AUTOSAR XML (schema 4-2-2)
package /ServiceApplTemplate/SwComponentTypes
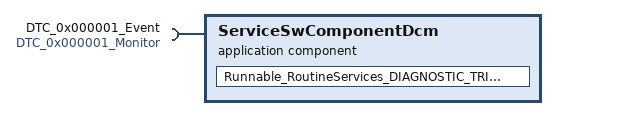
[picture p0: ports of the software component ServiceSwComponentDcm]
  application sw component type ServiceSwComponentDcm
    require port DTC_0x000001_Event: required-interface=DTC_0x000001_Monitor
    behavior ServiceSwComponentDcm_IB: handle-termination-and-restart=NO-SUPPORT
      runnable Runnable_RoutineServices_DIAGNOSTIC_TRIGGER_DTC_A5663192471BAAA2C67D187118DC8330: symbol=ServiceSwComponentDcm_RoutineServices_DIAGNOSTIC_TRIGGER_DTC_Start
        sync call SetEventStatus: operation=DTC_0x000001_Event.SetEventStatus, timeout=0.0
package /DemoApplication/SwComponentTypes
  composition sw component type TopLevelComposition
    component ServiceSwComponentDcm: type=ServiceSwComponentDcm
    connect Dem_Prototype.Event_DTC_0x000001_Event -> ServiceSwComponentDcm.DTC_0x000001_Event
package /PortInterfaces
  client server interface DTC_0x000001_Monitor: is-service=true
    operation SetEventStatus: possible-error=[E_NOT_OK, E_OK]
      arg EventStatus: type=Dem_EventStatusType, direction=IN
    error E_NOT_OK: error-code=1
    error E_OK: error-code=0
package /CompuMethods
  compu method CM_EventStatusType: 0=DEM_EVENT_STATUS_PASSED, 1=DEM_EVENT_STATUS_FAILED, 2=DEM_EVENT_STATUS_PREPASSED, 3=DEM_EVENT_STATUS_PREFAILED
package /DataConstr
  range CONSTR_EventStatusType: raw 0..3
